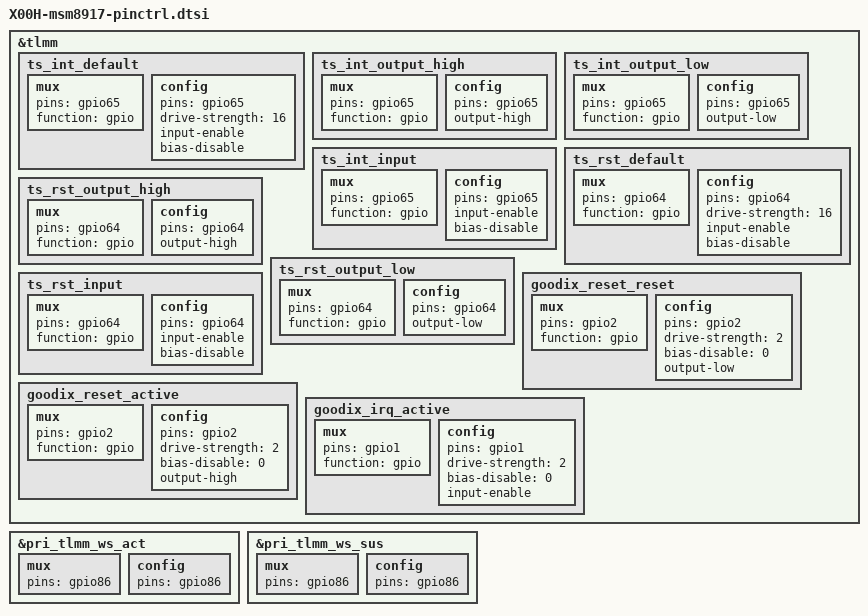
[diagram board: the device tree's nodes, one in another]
/*
 * Copyright (c) 2017, The Linux Foundation. All rights reserved.
 *
 * This program is free software; you can redistribute it and/or modify
 * it under the terms of the GNU General Public License version 2 and
 * only version 2 as published by the Free Software Foundation.
 *
 * This program is distributed in the hope that it will be useful,
 * but WITHOUT ANY WARRANTY; without even the implied warranty of
 * MERCHANTABILITY or FITNESS FOR A PARTICULAR PURPOSE.  See the
 * GNU General Public License for more details.
 */

&tlmm {
	/* add pingrp for goodix touch */
	ts_int_default: ts_int_default {
		mux {
			pins = "gpio65";
			function = "gpio";
		};
		config {
			pins = "gpio65";
			drive-strength = <16>;
			/*bias-pull-up;*/
			input-enable;
			bias-disable;
		};
	};

	ts_int_output_high: ts_int_output_high {
		mux {
			pins = "gpio65";
			function = "gpio";
		};
		config {
			pins = "gpio65";
			output-high;
		};
	};

	ts_int_output_low: ts_int_output_low {
		mux {
			pins = "gpio65";
			function = "gpio";
		};
		config {
			pins = "gpio65";
			output-low;
		};
	};

	ts_int_input: ts_int_input {
		mux {
			pins = "gpio65";
			function = "gpio";
		};
		config {
			pins = "gpio65";
			input-enable;
			bias-disable;
		};
	};

	ts_rst_default: ts_rst_default {
		mux {
			pins = "gpio64";
			function = "gpio";
		};
		config {
			pins = "gpio64";
			drive-strength = <16>;
			/*bias-pull-up;*/
			input-enable;
			bias-disable;
		};
	};

	ts_rst_output_high: ts_rst_output_high {
		mux {
			pins = "gpio64";
			function = "gpio";
		};
		config {
			pins = "gpio64";
			output-high;
		};
	};

	ts_rst_output_low: ts_rst_output_low {
		mux {
			pins = "gpio64";
			function = "gpio";
		};
		config {
			pins = "gpio64";
			output-low;
		};
	};

	ts_rst_input: ts_rst_input {
		mux {
			pins = "gpio64";
			function = "gpio";
		};
		config {
			pins = "gpio64";
			input-enable;
			bias-disable;
		};
	};

	goodix_reset_reset: goodix_reset_reset {
		mux {
				pins = "gpio2";
				function = "gpio";
		};

		config {
				pins = "gpio2";
				drive-strength = <2>;
				bias-disable = <0>;
				output-low;
		};
	};

	goodix_reset_active: goodix_reset_active {
		mux {
				pins = "gpio2";
				function = "gpio";
		};

		config {
				pins = "gpio2";
				drive-strength = <2>;
				bias-disable = <0>;
				output-high;
		};
	};

	goodix_irq_active: goodix_irq_active {
		mux {
				pins = "gpio1";
				function = "gpio";
		};

		config {
				pins = "gpio1";
				drive-strength = <2>;
				bias-disable = <0>;
				input-enable;
		};
	};
};

&pri_tlmm_ws_act {
	mux {
		pins = "gpio86";
	};

	config {
		pins = "gpio86";
	};
};

&pri_tlmm_ws_sus {
	mux {
		pins = "gpio86";
	};

	config {
		pins = "gpio86";
	};
};
